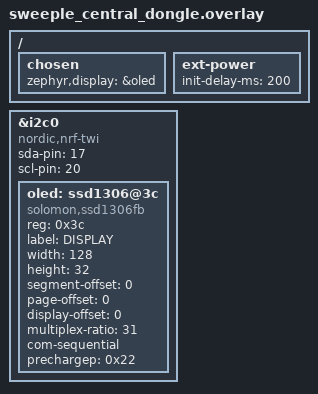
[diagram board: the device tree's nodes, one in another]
/*
 * Copyright (c) 2022 Atneya Nair
 *
 * SPDX-License-Identifier: MIT
 */


/ {
	chosen {
		zephyr,display = &oled;
	};
};

/ {
   ext-power { init-delay-ms = <200>; };
};

&i2c0 {
	status = "okay";
	sda-pin = <17>;
	scl-pin = <20>;
    compatible = "nordic,nrf-twi";
	oled: ssd1306@3c {
		compatible = "solomon,ssd1306fb";
		reg = <0x3c>;
		label = "DISPLAY";
		width = <128>;
		height = <32>;
		segment-offset = <0>;
		page-offset = <0>;
		display-offset = <0>;
		multiplex-ratio = <31>;
		com-sequential;
		prechargep = <0x22>;
	};
};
